# STM32H563 register map
File version: 0.4
CPU: CM33 r0p0, little endian, MPU, FPU, 4 interrupt priority bits
Registers are 32-bit, read-write, reset 0x0 unless marked. A register's access mark holds for its fields unless they carry their own. Offsets are from the block's base; [hi:lo] are bit positions; {n}, {i} and the like mark numbered series.

## DLYBOS1 — Delay block
Base 0x4600F000
Same registers: DLYBSD1 0x46008400, DLYBSD2 0x46008800, SEC_DLYBSD1 0x56008400, SEC_DLYBSD2 0x56008800, SEC_DLYBOS1 0x5600F000
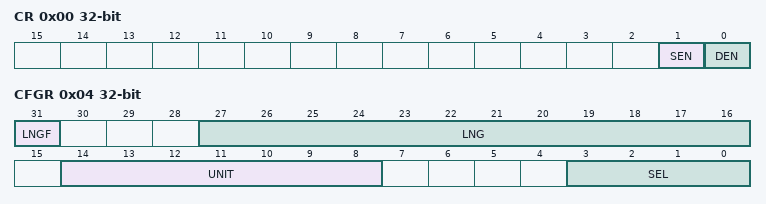
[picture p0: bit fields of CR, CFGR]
0x00 CR — control register
  [1] SEN — OPALPM
  [0] DEN — Operational amplifier Enable
0x04 CFGR access per field — configuration register
  [31] LNGF ro, [27:16] LNG ro, [14:8] UNIT rw, [3:0] SEL rw

## GTZC1_MPCBB1
Base 0x40032C00
Same registers: SEC_GTZC1_MPCBB1 0x50032C00
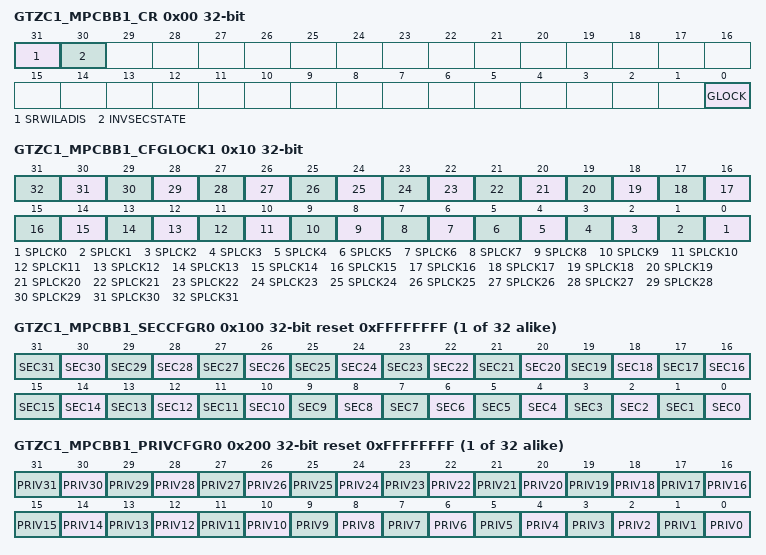
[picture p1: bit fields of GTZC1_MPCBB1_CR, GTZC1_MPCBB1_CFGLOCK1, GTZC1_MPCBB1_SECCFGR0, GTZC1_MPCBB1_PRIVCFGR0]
0x00 GTZC1_MPCBB1_CR — GTZC1 SRAM1 MPCBB control register
  [31] SRWILADIS — secure read/write illegal access disable This bit disables the detection of an illegal access when a secure read/write transaction access a non-secure blocks of the block-based SRAM (secure fetch on non-secure block is always considered illegal).
  [30] INVSECSTATE — SRAMx clocks security state This bit is used to define the internal SRAMs clocks control in RCC as secure or not.
  [0] GLOCK — lock the control register of the MPCBB until next reset This bit is cleared by default and once set, it can not be reset until system reset.
0x10 GTZC1_MPCBB1_CFGLOCK1 — GTZC1 SRAM1 MPCBB configuration lock register 1
  [n] SPLCK{n} (n=0..31) — Security/privilege configuration lock for super-block This bit is set by software and can be cleared only by system reset.
{0x100+4i} GTZC1_MPCBB1_SECCFGR{i} reset 0xFFFFFFFF (i=0..31) — GTZC1 SRAM1 MPCBB security configuration for super-block {i} register
  [n] SEC{n} (n=0..31) — Security configuration for block y Unprivileged write to this bit is ignored if PRIVy bit is set in GTZC1_MPCBBz_PRIVCFGRx. Writes are ignored if SPLCKx bit is set in GTZC1_MPCBBz_CFGLOCK.
{0x200+4i} GTZC1_MPCBB1_PRIVCFGR{i} reset 0xFFFFFFFF (i=0..31) — GTZC1 SRAM1 MPCBB privileged configuration for super-block {i} register
  [n] PRIV{n} (n=0..31) — Privileged configuration for block y, belonging to super-block x (y = 31 to 0). Non-secure write to this bit is ignored if SECy bit is set in GTZC1_MPCBBz_SECCFGRx. Writes are ignored if SPLCKx bit is set in GTZC1_MPCBBz_CFGLOCK.

## GTZC1_MPCBB2
Base 0x40033000
Same registers: SEC_GTZC1_MPCBB2 0x50033000
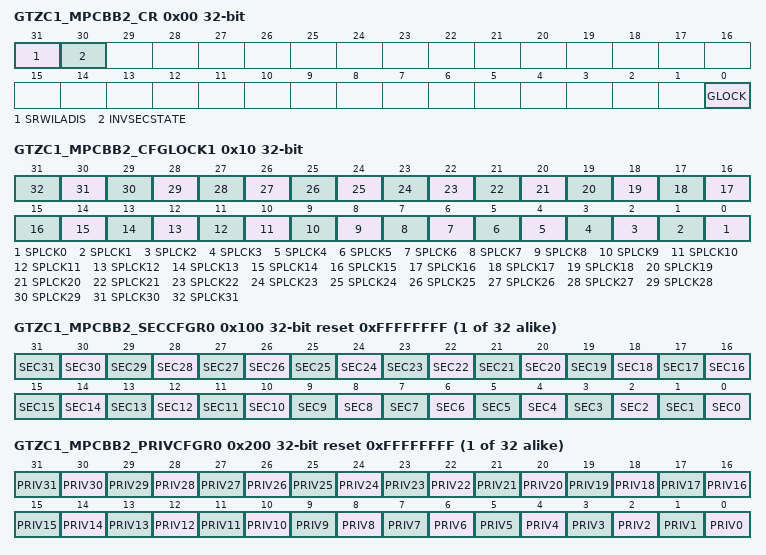
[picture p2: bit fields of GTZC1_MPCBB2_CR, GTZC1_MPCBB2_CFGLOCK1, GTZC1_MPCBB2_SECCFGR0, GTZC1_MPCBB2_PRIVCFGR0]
0x00 GTZC1_MPCBB2_CR — GTZC1 SRAM2 MPCBB control register
  [31] SRWILADIS — secure read/write illegal access disable This bit disables the detection of an illegal access when a secure read/write transaction access a non-secure blocks of the block-based SRAM (secure fetch on non-secure block is always considered illegal).
  [30] INVSECSTATE — SRAMx clocks security state This bit is used to define the internal SRAMs clocks control in RCC as secure or not.
  [0] GLOCK — lock the control register of the MPCBB until next reset This bit is cleared by default and once set, it can not be reset until system reset.
0x10 GTZC1_MPCBB2_CFGLOCK1 — GTZC1 SRAM2 MPCBB configuration lock register 1
  [n] SPLCK{n} (n=0..31) — Security/privilege configuration lock for super-block This bit is set by software and can be cleared only by system reset.
{0x100+4i} GTZC1_MPCBB2_SECCFGR{i} reset 0xFFFFFFFF (i=0..31) — GTZC1 SRAM2 MPCBB security configuration for super-block {i} register
  [n] SEC{n} (n=0..31) — Security configuration for block y Unprivileged write to this bit is ignored if PRIVy bit is set in GTZC1_MPCBBz_PRIVCFGRx. Writes are ignored if SPLCKx bit is set in GTZC1_MPCBBz_CFGLOCK.
{0x200+4i} GTZC1_MPCBB2_PRIVCFGR{i} reset 0xFFFFFFFF (i=0..31) — GTZC1 SRAM2 MPCBB privileged configuration for super-block {i} register
  [n] PRIV{n} (n=0..31) — Privileged configuration for block y, belonging to super-block x (y = 31 to 0). Non-secure write to this bit is ignored if SECy bit is set in GTZC1_MPCBBz_SECCFGRx. Writes are ignored if SPLCKx bit is set in GTZC1_MPCBBz_CFGLOCK.
